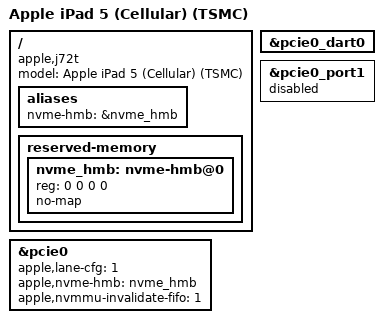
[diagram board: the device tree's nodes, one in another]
// SPDX-License-Identifier: GPL-2.0+ OR MIT
/*
 * Apple iPad 5 (Cellular) (TSMC), J72t, iPad6,12 (A1823)
 * Copyright (c) 2022, Konrad Dybcio <konradybcio@kernel.org>
 */

/dts-v1/;

#include "s8003.dtsi"
#include "s800x-ipad5.dtsi"

/ {
	compatible = "apple,j72t", "apple,s8003", "apple,arm-platform";
	model = "Apple iPad 5 (Cellular) (TSMC)";

	aliases {
		nvme-hmb = &nvme_hmb; /* Used by loader */
	};

	reserved-memory {
		nvme_hmb: nvme-hmb@0 {
			reg = <0 0 0 0>; /* To be filled by loader */
			no-map;
		};
	};
};

&pcie0_dart0 {
	status = "okay";
};

&pcie0 {
	apple,lane-cfg = <1>;
	apple,nvme-hmb = <&nvme_hmb>;
	/* live ADT nvme-mmu0 invalidate-fifo-workaround (added by iBoot) */
	apple,nvmmu-invalidate-fifo = <1>;
	status = "okay";
};

/*
 * The BCM4355 needs a power sequence (PMU-controlled VDD, wlan-uart
 * provider) before its link can train; until that exists, leave port 1
 * and its DART off.
 */
&pcie0_port1 {
	status = "disabled";
};
